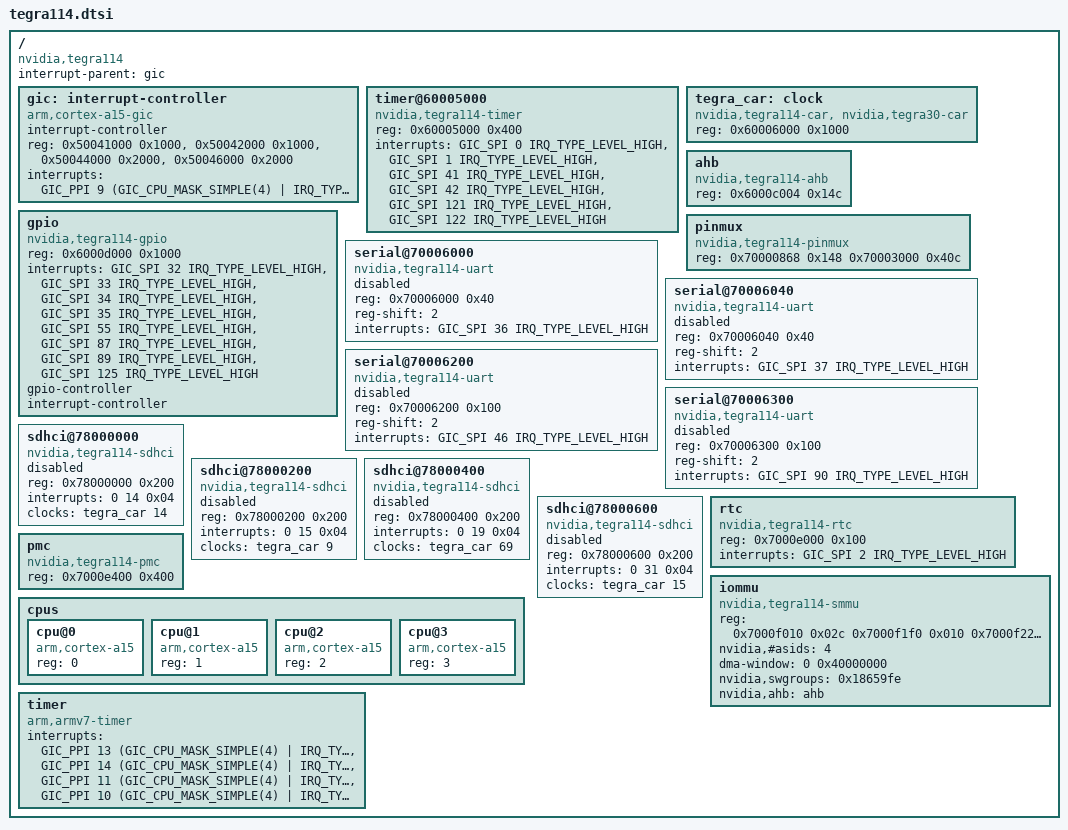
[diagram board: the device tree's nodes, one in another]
#include <dt-bindings/gpio/tegra-gpio.h>
#include <dt-bindings/interrupt-controller/arm-gic.h>

#include "skeleton.dtsi"

/ {
	compatible = "nvidia,tegra114";
	interrupt-parent = <&gic>;

	gic: interrupt-controller {
		compatible = "arm,cortex-a15-gic";
		#interrupt-cells = <3>;
		interrupt-controller;
		reg = <0x50041000 0x1000>,
		      <0x50042000 0x1000>,
		      <0x50044000 0x2000>,
		      <0x50046000 0x2000>;
		interrupts = <GIC_PPI 9
			(GIC_CPU_MASK_SIMPLE(4) | IRQ_TYPE_LEVEL_HIGH)>;
	};

	timer@60005000 {
		compatible = "nvidia,tegra114-timer", "nvidia,tegra20-timer";
		reg = <0x60005000 0x400>;
		interrupts = <GIC_SPI 0 IRQ_TYPE_LEVEL_HIGH>,
			     <GIC_SPI 1 IRQ_TYPE_LEVEL_HIGH>,
			     <GIC_SPI 41 IRQ_TYPE_LEVEL_HIGH>,
			     <GIC_SPI 42 IRQ_TYPE_LEVEL_HIGH>,
			     <GIC_SPI 121 IRQ_TYPE_LEVEL_HIGH>,
			     <GIC_SPI 122 IRQ_TYPE_LEVEL_HIGH>;
	};

	tegra_car: clock {
		compatible = "nvidia,tegra114-car, nvidia,tegra30-car";
		reg = <0x60006000 0x1000>;
		#clock-cells = <1>;
	};

	ahb: ahb {
		compatible = "nvidia,tegra114-ahb", "nvidia,tegra30-ahb";
		reg = <0x6000c004 0x14c>;
	};

	gpio: gpio {
		compatible = "nvidia,tegra114-gpio", "nvidia,tegra30-gpio";
		reg = <0x6000d000 0x1000>;
		interrupts = <GIC_SPI 32 IRQ_TYPE_LEVEL_HIGH>,
			     <GIC_SPI 33 IRQ_TYPE_LEVEL_HIGH>,
			     <GIC_SPI 34 IRQ_TYPE_LEVEL_HIGH>,
			     <GIC_SPI 35 IRQ_TYPE_LEVEL_HIGH>,
			     <GIC_SPI 55 IRQ_TYPE_LEVEL_HIGH>,
			     <GIC_SPI 87 IRQ_TYPE_LEVEL_HIGH>,
			     <GIC_SPI 89 IRQ_TYPE_LEVEL_HIGH>,
			     <GIC_SPI 125 IRQ_TYPE_LEVEL_HIGH>;
		#gpio-cells = <2>;
		gpio-controller;
		#interrupt-cells = <2>;
		interrupt-controller;
	};

	pinmux: pinmux {
		compatible = "nvidia,tegra114-pinmux";
		reg = <0x70000868 0x148		/* Pad control registers */
		       0x70003000 0x40c>;	/* Mux registers */
	};

	serial@70006000 {
		compatible = "nvidia,tegra114-uart", "nvidia,tegra20-uart";
		reg = <0x70006000 0x40>;
		reg-shift = <2>;
		interrupts = <GIC_SPI 36 IRQ_TYPE_LEVEL_HIGH>;
		status = "disabled";
	};

	serial@70006040 {
		compatible = "nvidia,tegra114-uart", "nvidia,tegra20-uart";
		reg = <0x70006040 0x40>;
		reg-shift = <2>;
		interrupts = <GIC_SPI 37 IRQ_TYPE_LEVEL_HIGH>;
		status = "disabled";
	};

	serial@70006200 {
		compatible = "nvidia,tegra114-uart", "nvidia,tegra20-uart";
		reg = <0x70006200 0x100>;
		reg-shift = <2>;
		interrupts = <GIC_SPI 46 IRQ_TYPE_LEVEL_HIGH>;
		status = "disabled";
	};

	serial@70006300 {
		compatible = "nvidia,tegra114-uart", "nvidia,tegra20-uart";
		reg = <0x70006300 0x100>;
		reg-shift = <2>;
		interrupts = <GIC_SPI 90 IRQ_TYPE_LEVEL_HIGH>;
		status = "disabled";
	};

	sdhci@78000000 {
		compatible = "nvidia,tegra114-sdhci", "nvidia,tegra30-sdhci";
		reg = <0x78000000 0x200>;
		interrupts = <0 14 0x04>;
		clocks = <&tegra_car 14>;
		status = "disable";
	};

	sdhci@78000200 {
		compatible = "nvidia,tegra114-sdhci", "nvidia,tegra30-sdhci";
		reg = <0x78000200 0x200>;
		interrupts = <0 15 0x04>;
		clocks = <&tegra_car 9>;
		status = "disable";
	};

	sdhci@78000400 {
		compatible = "nvidia,tegra114-sdhci", "nvidia,tegra30-sdhci";
		reg = <0x78000400 0x200>;
		interrupts = <0 19 0x04>;
		clocks = <&tegra_car 69>;
		status = "disable";
	};

	sdhci@78000600 {
		compatible = "nvidia,tegra114-sdhci", "nvidia,tegra30-sdhci";
		reg = <0x78000600 0x200>;
		interrupts = <0 31 0x04>;
		clocks = <&tegra_car 15>;
		status = "disable";
	};

	rtc {
		compatible = "nvidia,tegra114-rtc", "nvidia,tegra20-rtc";
		reg = <0x7000e000 0x100>;
		interrupts = <GIC_SPI 2 IRQ_TYPE_LEVEL_HIGH>;
	};

	pmc {
		compatible = "nvidia,tegra114-pmc";
		reg = <0x7000e400 0x400>;
	};

	iommu {
		compatible = "nvidia,tegra114-smmu", "nvidia,tegra30-smmu";
		reg = <0x7000f010 0x02c
		       0x7000f1f0 0x010
		       0x7000f228 0x074>;
		nvidia,#asids = <4>;
		dma-window = <0 0x40000000>;
		nvidia,swgroups = <0x18659fe>;
		nvidia,ahb = <&ahb>;
	};

	cpus {
		#address-cells = <1>;
		#size-cells = <0>;

		cpu@0 {
			device_type = "cpu";
			compatible = "arm,cortex-a15";
			reg = <0>;
		};

		cpu@1 {
			device_type = "cpu";
			compatible = "arm,cortex-a15";
			reg = <1>;
		};

		cpu@2 {
			device_type = "cpu";
			compatible = "arm,cortex-a15";
			reg = <2>;
		};

		cpu@3 {
			device_type = "cpu";
			compatible = "arm,cortex-a15";
			reg = <3>;
		};
	};

	timer {
		compatible = "arm,armv7-timer";
		interrupts =
			<GIC_PPI 13
				(GIC_CPU_MASK_SIMPLE(4) | IRQ_TYPE_LEVEL_LOW)>,
			<GIC_PPI 14
				(GIC_CPU_MASK_SIMPLE(4) | IRQ_TYPE_LEVEL_LOW)>,
			<GIC_PPI 11
				(GIC_CPU_MASK_SIMPLE(4) | IRQ_TYPE_LEVEL_LOW)>,
			<GIC_PPI 10
				(GIC_CPU_MASK_SIMPLE(4) | IRQ_TYPE_LEVEL_LOW)>;
	};
};
